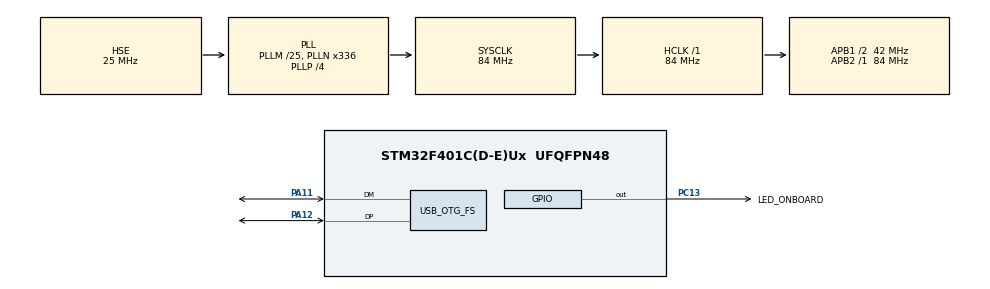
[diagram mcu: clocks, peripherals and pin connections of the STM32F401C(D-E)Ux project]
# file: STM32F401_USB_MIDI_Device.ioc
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Mcu.Family=STM32F4
Mcu.Name=STM32F401C(D-E)Ux
Mcu.Package=UFQFPN48
NVIC.OTG_FS_IRQn=true\:0\:0\:false\:false\:true\:true\:true\:true
NVIC.PriorityGroup=NVIC_PRIORITYGROUP_4
NVIC.TIM1_TRG_COM_TIM11_IRQn=true\:0\:0\:false\:false\:true\:true\:true\:true
PA11.Mode=Device_Only
PA11.Signal=USB_OTG_FS_DM
PA12.Mode=Device_Only
PA12.Signal=USB_OTG_FS_DP
PA13.Mode=Serial_Wire
PA13.Signal=SYS_JTMS-SWDIO
PA14.Mode=Serial_Wire
PA14.Signal=SYS_JTCK-SWCLK
PC13-ANTI_TAMP.GPIO_Label=LED_ONBOARD
PC13-ANTI_TAMP.Signal=GPIO_Output
PH0\ -\ OSC_IN.Mode=HSE-External-Oscillator
PH0\ -\ OSC_IN.Signal=RCC_OSC_IN
PH1\ -\ OSC_OUT.Mode=HSE-External-Oscillator
PH1\ -\ OSC_OUT.Signal=RCC_OSC_OUT
ProjectManager.HeapSize=0x200
ProjectManager.StackSize=0x400
ProjectManager.TargetToolchain=STM32CubeIDE
RCC.48MHZClocksFreq_Value=48000000
RCC.AHBFreq_Value=84000000
RCC.APB1CLKDivider=RCC_HCLK_DIV2
RCC.APB1Freq_Value=42000000
RCC.APB1TimFreq_Value=84000000
RCC.APB2Freq_Value=84000000
RCC.APB2TimFreq_Value=84000000
RCC.CortexFreq_Value=84000000
RCC.HCLKFreq_Value=84000000
RCC.HSE_VALUE=25000000
RCC.HSI_VALUE=16000000
RCC.LSE_VALUE=32768
RCC.PLLM=25
RCC.PLLN=336
RCC.PLLP=RCC_PLLP_DIV4
RCC.PLLQ=7
RCC.SYSCLKFreq_VALUE=84000000
RCC.SYSCLKSource=RCC_SYSCLKSOURCE_PLLCLK
RCC.VCOOutputFreq_Value=336000000
TIM11.Period=4999
TIM11.Prescaler=8399
USB_DEVICE.CLASS_NAME_FS=CUSTOM_HID
USB_DEVICE.CONFIGURATION_STRING_CUSTOMHID_FS=STM32 MIDI Config
USB_DEVICE.INTERFACE_STRING_CUSTOMHID_FS=STM32 MIDI Interface
USB_DEVICE.PRODUCT_STRING_CUSTOMHID_FS=STM32 MIDI Device
USB_DEVICE.VirtualMode-CUSTOM_HID_FS=CustomHid
USB_DEVICE.VirtualModeFS=Custom_Hid_FS
USB_OTG_FS.VirtualMode=Device_Only
VP_TIM11_VS_ClockSourceINT.Mode=Enable_Timer
VP_USB_DEVICE_VS_USB_DEVICE_CUSTOM_HID_FS.Mode=CUSTOM_HID_FS
board=custom

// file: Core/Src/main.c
/* USER CODE BEGIN Header */
/**
  ******************************************************************************
  * @file           : main.c
  * @brief          : Main program body
  ******************************************************************************
  * @attention
  *
  * Copyright (c) 2024 STMicroelectronics.
  * All rights reserved.
  *
  * This software is licensed under terms that can be found in the LICENSE file
  * in the root directory of this software component.
  * If no LICENSE file comes with this software, it is provided AS-IS.
  *
  ******************************************************************************
  */
/* USER CODE END Header */
#include "main.h"
#include "tim.h"
#include "usb_device.h"
#include "gpio.h"

/* USER CODE BEGIN Includes */
#include "usbd_midi_if.h"
/* USER CODE END Includes */

/* USER CODE BEGIN PD */
#define MIDI_CHANNEL		00
#define MIDI_CABLE			00
/* USER CODE END PD */

/* USER CODE BEGIN PV */

/* Flags: */
uint8_t flag_tim11 = 0;
uint8_t midi_nt_received_flag = 1;	// MIDI note message received flag.
uint8_t midi_pc_received_flag = 1;	// MIDI program change message received flag.
uint8_t midi_cc_received_flag = 1;	// MIDI control change message received flag.

/* MIDI unions: */
MIDI_NoteUnion_typedef midi_note_tx;		// MIDI note message variable (transmit)
MIDI_NoteUnion_typedef midi_note_rx;		// MIDI note message variable (received)
MIDI_ProgChangeUnion_typedef midi_pc_tx;	// MIDI program change message variable (transmit)
MIDI_ProgChangeUnion_typedef midi_pc_rx;	// MIDI program change message variable (received)
MIDI_CtrChangeUnion_typedef midi_cc_tx;		// MIDI control change message variable (transmit)
MIDI_CtrChangeUnion_typedef midi_cc_rx;		// MIDI control change message variable (received)

/* USER CODE END PV */

void SystemClock_Config(void);

int main(void)
{

  /* USER CODE BEGIN 1 */
	// MIDI Note message data initialization:
	midi_note_tx.fields.cable = MIDI_CABLE;
	//midi_note.fields.CIN = 0x09; // MIDI note on. This atribution is optional.
	midi_note_tx.fields.channel = MIDI_CHANNEL;
	midi_note_tx.fields.type = MIDI_NOTE_ON;
	midi_note_tx.fields.note = 0x26;
	midi_note_tx.fields.velocity = 0x7F; // 127

	// MIDI Program change message data initialization:
	midi_pc_tx.fields.cable = MIDI_CABLE;
	midi_pc_tx.fields.CIN = 0x0C;  // This atribution is optional.
	midi_pc_tx.fields.channel = MIDI_CHANNEL;
	midi_pc_tx.fields.type = 0x0C; // This atribution is optional.
	midi_pc_tx.fields.program = 2;
	midi_pc_tx.fields.unused = 0;  // This atribution is optional.

	// MIDI Control change message data initialization:
	midi_cc_tx.fields.cable = MIDI_CABLE;
	midi_cc_tx.fields.channel = MIDI_CHANNEL;
	midi_cc_tx.fields.controller = 0x2A;
	midi_cc_tx.fields.value = 0x7F; // Valeu 127: ON state

	uint8_t temp1 = 0;
  /* USER CODE END 1 */

  /* MCU Configuration--------------------------------------------------------*/

  /* Reset of all peripherals, Initializes the Flash interface and the Systick. */
  HAL_Init();

  /* Configure the system clock */
  SystemClock_Config();

  /* Initialize all configured peripherals */
  MX_GPIO_Init();
  MX_TIM11_Init();
  MX_USB_DEVICE_Init();
  /* USER CODE BEGIN 2 */
	/* Starting timers: */
	HAL_TIM_Base_Start_IT(&htim11); // TIM11 used for counting half seconds (blink led)
  /* USER CODE END 2 */

  /* Infinite loop */
	while (1)
	{

    /* USER CODE BEGIN 3 */

		if(flag_tim11 == 1){ // Half second has passed.
			// Led Blink:
			HAL_GPIO_TogglePin(LED_ONBOARD_GPIO_Port, LED_ONBOARD_Pin);
			flag_tim11 = 0;
			if (temp1 == 1){
				midi_note_tx.fields.note = 0x26; // Snare (on Hydrogen MIDI in)
				temp1 = 0;
			}else{
				midi_note_tx.fields.note = 0x24; // Kick drum (on Hydrogen MIDI in)
				temp1 = 1;
			}
			MIDI_SendNote(&midi_note_tx); // To send a MIDI note message
			//MIDI_SendProgramChange(&midi_pc); // To send a MIDI Program Change message
			//midi_pc.fields.program = midi_pc.fields.program + 10; // just for testing
			//MIDI_SendControlChange(&midi_cc); // To send a MIDI Controller Change message
			//midi_cc.fields.value = midi_cc.fields.value + 10; // just for testing
		} // flag_tim11 == 1

	}
  /* USER CODE END 3 */
}

void SystemClock_Config(void)
{
  RCC_OscInitTypeDef RCC_OscInitStruct = {0};
  RCC_ClkInitTypeDef RCC_ClkInitStruct = {0};

  /** Configure the main internal regulator output voltage
  */
  __HAL_RCC_PWR_CLK_ENABLE();
  __HAL_PWR_VOLTAGESCALING_CONFIG(PWR_REGULATOR_VOLTAGE_SCALE2);

  /** Initializes the RCC Oscillators according to the specified parameters
  * in the RCC_OscInitTypeDef structure.
  */
  RCC_OscInitStruct.OscillatorType = RCC_OSCILLATORTYPE_HSE;
  RCC_OscInitStruct.HSEState = RCC_HSE_ON;
  RCC_OscInitStruct.PLL.PLLState = RCC_PLL_ON;
  RCC_OscInitStruct.PLL.PLLSource = RCC_PLLSOURCE_HSE;
  RCC_OscInitStruct.PLL.PLLM = 25;
  RCC_OscInitStruct.PLL.PLLN = 336;
  RCC_OscInitStruct.PLL.PLLP = RCC_PLLP_DIV4;
  RCC_OscInitStruct.PLL.PLLQ = 7;
  if (HAL_RCC_OscConfig(&RCC_OscInitStruct) != HAL_OK)
  {
    Error_Handler();
  }

  /** Initializes the CPU, AHB and APB buses clocks
  */
  RCC_ClkInitStruct.ClockType = RCC_CLOCKTYPE_HCLK|RCC_CLOCKTYPE_SYSCLK
                              |RCC_CLOCKTYPE_PCLK1|RCC_CLOCKTYPE_PCLK2;
  RCC_ClkInitStruct.SYSCLKSource = RCC_SYSCLKSOURCE_PLLCLK;
  RCC_ClkInitStruct.AHBCLKDivider = RCC_SYSCLK_DIV1;
  RCC_ClkInitStruct.APB1CLKDivider = RCC_HCLK_DIV2;
  RCC_ClkInitStruct.APB2CLKDivider = RCC_HCLK_DIV1;

  if (HAL_RCC_ClockConfig(&RCC_ClkInitStruct, FLASH_LATENCY_2) != HAL_OK)
  {
    Error_Handler();
  }
}

/* USER CODE BEGIN 4 */

/* This callback is executed when the USB MIDI Class receives a MIDI note message. */
void MIDI_ReceivedNoteCallback(MIDI_NoteUnion_typedef receivedNote){
	/* Doing stuff in main loop. */
	memcpy(midi_note_rx.array, receivedNote.array, 4);
	/* TODO: declare global midi received variables in usbd_midi_if.c */
	midi_nt_received_flag = 1;

}

/* This callback is executed when the USB MIDI Class receives a MIDI Program Change message. */
void MIDI_ReceivedProgramChangeCallback(MIDI_ProgChangeUnion_typedef receivedProgramChange){
	/* Doing stuff in main loop. */
	memcpy(midi_pc_rx.array, receivedProgramChange.array, 4);
	/* TODO: declare global midi received variables in usbd_midi_if.c */
	midi_pc_received_flag = 1;

}

/* This callback is executed when the USB MIDI Class receives a MIDI Contro Change message. */
void MIDI_ReceivedControlChangeCallback(MIDI_CtrChangeUnion_typedef receivedControlChange){
	/* Doing stuff in main loop. */
	memcpy(midi_cc_rx.array, receivedControlChange.array, 4);
	/* TODO: declare global midi received variables in usbd_midi_if.c */
	midi_cc_received_flag = 1;
}

/* Timer interrupt callback */
void HAL_TIM_PeriodElapsedCallback(TIM_HandleTypeDef *htim){
	if (htim->Instance == TIM11){
		flag_tim11 = 1;
	} // htim->Instance == TIM11
} // HAL_TIM_PeriodElapsedCallback

/* USER CODE END 4 */

void Error_Handler(void)
{
  __disable_irq();
  while (1)
  {
  }
}
